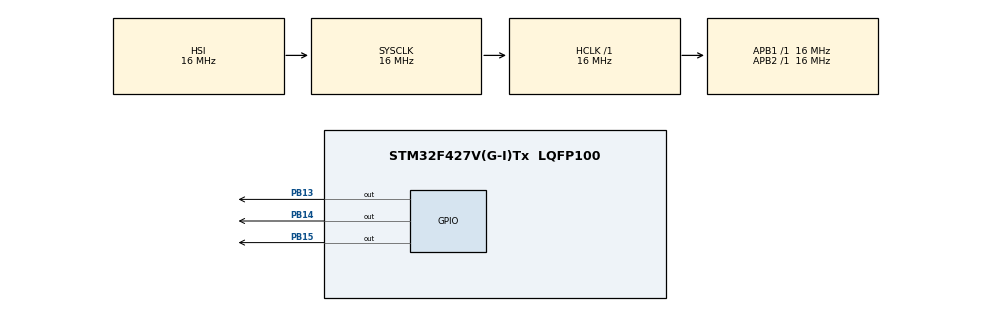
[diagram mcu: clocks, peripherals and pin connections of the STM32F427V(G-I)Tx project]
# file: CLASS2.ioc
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Mcu.Family=STM32F4
Mcu.Name=STM32F427V(G-I)Tx
Mcu.Package=LQFP100
NVIC.PriorityGroup=NVIC_PRIORITYGROUP_4
PA13.Mode=JTAG_5_pins
PA13.Signal=SYS_JTMS-SWDIO
PA14.Mode=JTAG_5_pins
PA14.Signal=SYS_JTCK-SWCLK
PA15.Mode=JTAG_5_pins
PA15.Signal=SYS_JTDI
PB13.Signal=GPIO_Output
PB14.Signal=GPIO_Output
PB15.Signal=GPIO_Output
PB3.Mode=JTAG_5_pins
PB3.Signal=SYS_JTDO-SWO
PB4.Mode=JTAG_5_pins
PB4.Signal=SYS_JTRST
ProjectManager.HeapSize=0x200
ProjectManager.StackSize=0x400
ProjectManager.TargetToolchain=STM32CubeIDE
RCC.AHBFreq_Value=16000000
RCC.APB1Freq_Value=16000000
RCC.APB2Freq_Value=16000000
RCC.CortexFreq_Value=16000000
RCC.HSE_VALUE=25000000
RCC.HSI_VALUE=16000000
RCC.LSE_VALUE=32768
RCC.SYSCLKFreq_VALUE=16000000
RCC.VCOOutputFreq_Value=192000000
board=custom

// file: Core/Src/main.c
/* USER CODE BEGIN Header */
/**
  ******************************************************************************
  * @file           : main.c
  * @brief          : Main program body
  ******************************************************************************
  * @attention
  *
  * Copyright (c) 2024 STMicroelectronics.
  * All rights reserved.
  *
  * This software is licensed under terms that can be found in the LICENSE file
  * in the root directory of this software component.
  * If no LICENSE file comes with this software, it is provided AS-IS.
  *
  ******************************************************************************
  */
/* USER CODE END Header */
#include "main.h"
#include "gpio.h"

void SystemClock_Config(void);

/* USER CODE BEGIN 0 */
void calculator_reset() {
	calc.num1 = 0;
	calc.num2 = 0;
	calc.operation = 0;
	calc.input_stage = 0;
}

float calculate() {
	switch(calc.operation) {
		case '+':
			return calc.operand1 + calc.operand2;
	    case '-':
	        return calc.operand1 - calc.operand2;
	    case '*':
	        return calc.operand1 * calc.operand2;
	    case '/':
	        if (calc.operand2 != 0)
	        	return calc.operand1 / calc.operand2;
	        else
	        	return 0;
	    default:
	        return 0;
	   }
}

void button_press(char key) {
    switch (key) {
        case '0' ... '9':
            if (calc.input_stage == 0) {
                calc.operand1 = calc.operand1 * 10 + (key - '0');
            } else if (calc.input_stage == 2) {
                calc.operand2 = calc.operand2 * 10 + (key - '0');
            }
            break;
        case '+':
        case '-':
        case '*':
        case '/':
            calc.operation = key;
            calc.input_stage = 1;
            break;
        case '=':
            if (calc.input_stage == 1) {
                calc.input_stage = 2;
                float result = calculate();
                // OUT
                calculator_reset();
            }
            break;
        case 'C':
            calculator_reset();
            break;
    }
}
/* USER CODE END 0 */

int main(void)
{

  /* MCU Configuration--------------------------------------------------------*/

  /* Reset of all peripherals, Initializes the Flash interface and the Systick. */
  HAL_Init();

  /* Configure the system clock */
  SystemClock_Config();

  /* Initialize all configured peripherals */
  MX_GPIO_Init();

  /* Infinite loop */
  while (1)
  {
	  // INPUT
  }
}

void SystemClock_Config(void)
{
  RCC_OscInitTypeDef RCC_OscInitStruct = {0};
  RCC_ClkInitTypeDef RCC_ClkInitStruct = {0};

  /** Configure the main internal regulator output voltage
  */
  __HAL_RCC_PWR_CLK_ENABLE();
  __HAL_PWR_VOLTAGESCALING_CONFIG(PWR_REGULATOR_VOLTAGE_SCALE3);

  /** Initializes the RCC Oscillators according to the specified parameters
  * in the RCC_OscInitTypeDef structure.
  */
  RCC_OscInitStruct.OscillatorType = RCC_OSCILLATORTYPE_HSI;
  RCC_OscInitStruct.HSIState = RCC_HSI_ON;
  RCC_OscInitStruct.HSICalibrationValue = RCC_HSICALIBRATION_DEFAULT;
  RCC_OscInitStruct.PLL.PLLState = RCC_PLL_NONE;
  if (HAL_RCC_OscConfig(&RCC_OscInitStruct) != HAL_OK)
  {
    Error_Handler();
  }

  /** Initializes the CPU, AHB and APB buses clocks
  */
  RCC_ClkInitStruct.ClockType = RCC_CLOCKTYPE_HCLK|RCC_CLOCKTYPE_SYSCLK
                              |RCC_CLOCKTYPE_PCLK1|RCC_CLOCKTYPE_PCLK2;
  RCC_ClkInitStruct.SYSCLKSource = RCC_SYSCLKSOURCE_HSI;
  RCC_ClkInitStruct.AHBCLKDivider = RCC_SYSCLK_DIV1;
  RCC_ClkInitStruct.APB1CLKDivider = RCC_HCLK_DIV1;
  RCC_ClkInitStruct.APB2CLKDivider = RCC_HCLK_DIV1;

  if (HAL_RCC_ClockConfig(&RCC_ClkInitStruct, FLASH_LATENCY_0) != HAL_OK)
  {
    Error_Handler();
  }
}

void Error_Handler(void)
{
  __disable_irq();
  while (1)
  {
  }
}
